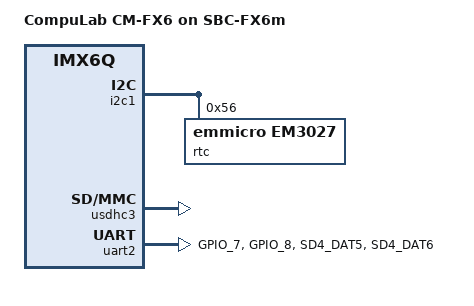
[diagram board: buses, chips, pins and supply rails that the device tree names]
/*
* Copyright 2014 CompuLab Ltd.
*
* Author: Valentin Raevsky <valentin@compulab.co.il>
*
* The code contained herein is licensed under the GNU General Public
* License. You may obtain a copy of the GNU General Public License
* Version 2 or later at the following locations:
*
* http://www.opensource.org/licenses/gpl-license.html
* http://www.gnu.org/copyleft/gpl.html
*/

/dts-v1/;
#include "imx6q-sb-fx6m.dtsi"
#include "imx6q-cm-fx6.dtsi"

/ {
	model = "CompuLab CM-FX6 on SBC-FX6m";	
	compatible = "compulab,cm-fx6", "compulab,sbc-fx6m", "fsl,imx6q";

};

&iomuxc {
	imx6q-sbc-fx6m {
		/* pins for uart2 */
		pinctrl_uart2: uart2grp {
			fsl,pins = <
				MX6QDL_PAD_GPIO_7__UART2_TX_DATA 0x1b0b1
				MX6QDL_PAD_GPIO_8__UART2_RX_DATA 0x1b0b1
				MX6QDL_PAD_SD4_DAT5__UART2_RTS_B 0x1b0b1
				MX6QDL_PAD_SD4_DAT6__UART2_CTS_B 0x1b0b1
		>;
		};
	};
};


&i2c1 {
	rtc@56 {
		compatible = "emmicro,em3027";
		reg = <0x56>;
	};
};

&usdhc3 {
	status = "okay";
};

/* rear serial console */
&uart2 {
	pinctrl-names = "default";
	pinctrl-0 = <&pinctrl_uart2>;
	/* fsl,dte-mode; */
	fsl,uart-has-rtscts;
	dma-names = "rx", "tx";
	dmas = <&sdma 27 4 0>, <&sdma 28 4 0>;
	status = "okay";
};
